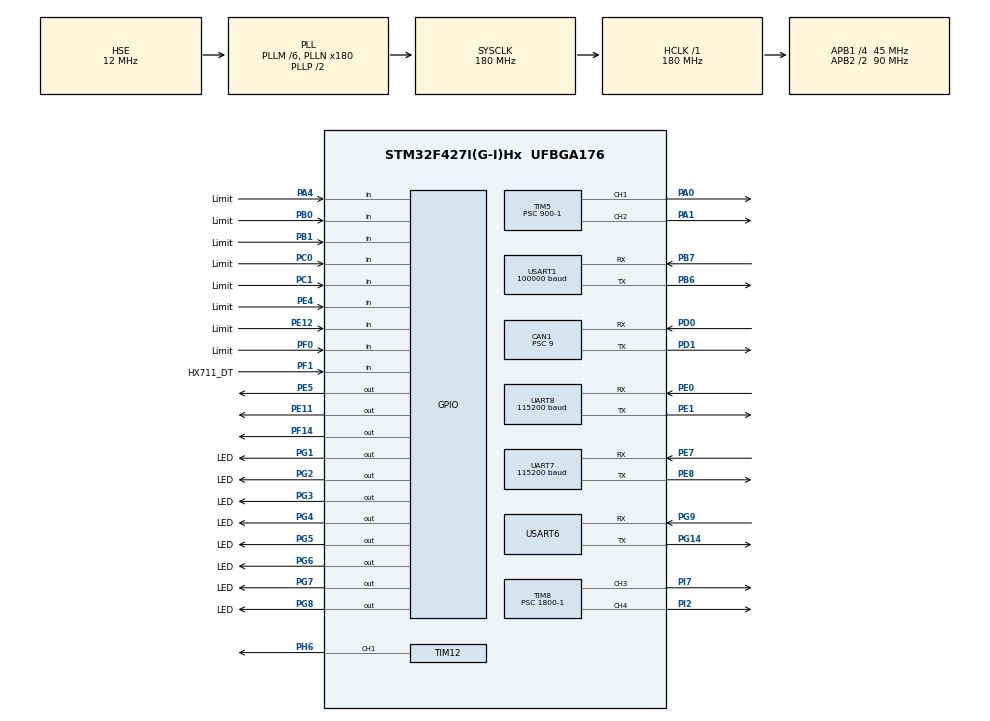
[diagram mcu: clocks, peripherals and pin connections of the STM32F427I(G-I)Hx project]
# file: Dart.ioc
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CAN1.BS1=CAN_BS1_2TQ
CAN1.BS2=CAN_BS2_2TQ
CAN1.CalculateBaudRate=1000000
CAN1.CalculateTimeBit=1000
CAN1.CalculateTimeQuantum=200.0
CAN1.Prescaler=9
Dma.Request0=UART8_RX
Dma.Request1=USART1_RX
Dma.Request2=UART8_TX
Dma.Request3=UART7_RX
Dma.Request4=UART7_TX
Dma.UART7_RX.3.Direction=DMA_PERIPH_TO_MEMORY
Dma.UART7_RX.3.FIFOMode=DMA_FIFOMODE_DISABLE
Dma.UART7_RX.3.Instance=DMA1_Stream3
Dma.UART7_RX.3.MemDataAlignment=DMA_MDATAALIGN_BYTE
Dma.UART7_RX.3.MemInc=DMA_MINC_ENABLE
Dma.UART7_RX.3.Mode=DMA_CIRCULAR
Dma.UART7_RX.3.PeriphDataAlignment=DMA_PDATAALIGN_BYTE
Dma.UART7_RX.3.PeriphInc=DMA_PINC_DISABLE
Dma.UART7_RX.3.Priority=DMA_PRIORITY_VERY_HIGH
Dma.UART7_TX.4.Direction=DMA_MEMORY_TO_PERIPH
Dma.UART7_TX.4.FIFOMode=DMA_FIFOMODE_DISABLE
Dma.UART7_TX.4.Instance=DMA1_Stream1
Dma.UART7_TX.4.MemDataAlignment=DMA_MDATAALIGN_BYTE
Dma.UART7_TX.4.MemInc=DMA_MINC_ENABLE
Dma.UART7_TX.4.Mode=DMA_NORMAL
Dma.UART7_TX.4.PeriphDataAlignment=DMA_PDATAALIGN_BYTE
Dma.UART7_TX.4.PeriphInc=DMA_PINC_DISABLE
Dma.UART7_TX.4.Priority=DMA_PRIORITY_VERY_HIGH
Dma.UART8_RX.0.Direction=DMA_PERIPH_TO_MEMORY
Dma.UART8_RX.0.FIFOMode=DMA_FIFOMODE_DISABLE
Dma.UART8_RX.0.Instance=DMA1_Stream6
Dma.UART8_RX.0.MemDataAlignment=DMA_MDATAALIGN_BYTE
Dma.UART8_RX.0.MemInc=DMA_MINC_ENABLE
Dma.UART8_RX.0.Mode=DMA_NORMAL
Dma.UART8_RX.0.PeriphDataAlignment=DMA_PDATAALIGN_BYTE
Dma.UART8_RX.0.PeriphInc=DMA_PINC_DISABLE
Dma.UART8_RX.0.Priority=DMA_PRIORITY_VERY_HIGH
Dma.UART8_TX.2.Direction=DMA_MEMORY_TO_PERIPH
Dma.UART8_TX.2.FIFOMode=DMA_FIFOMODE_DISABLE
Dma.UART8_TX.2.Instance=DMA1_Stream0
Dma.UART8_TX.2.MemDataAlignment=DMA_MDATAALIGN_BYTE
Dma.UART8_TX.2.MemInc=DMA_MINC_ENABLE
Dma.UART8_TX.2.Mode=DMA_NORMAL
Dma.UART8_TX.2.PeriphDataAlignment=DMA_PDATAALIGN_BYTE
Dma.UART8_TX.2.PeriphInc=DMA_PINC_DISABLE
Dma.UART8_TX.2.Priority=DMA_PRIORITY_VERY_HIGH
Dma.USART1_RX.1.Direction=DMA_PERIPH_TO_MEMORY
Dma.USART1_RX.1.FIFOMode=DMA_FIFOMODE_DISABLE
Dma.USART1_RX.1.Instance=DMA2_Stream2
Dma.USART1_RX.1.MemDataAlignment=DMA_MDATAALIGN_BYTE
Dma.USART1_RX.1.MemInc=DMA_MINC_ENABLE
Dma.USART1_RX.1.Mode=DMA_NORMAL
Dma.USART1_RX.1.PeriphDataAlignment=DMA_PDATAALIGN_BYTE
Dma.USART1_RX.1.PeriphInc=DMA_PINC_DISABLE
Dma.USART1_RX.1.Priority=DMA_PRIORITY_VERY_HIGH
FREERTOS.Queues01=Queue_DT7ToGimbal,1,18,1,Dynamic,NULL,NULL
FREERTOS.Tasks01=MotorControlTask,24,512,Motor_Task_Entry,As weak,NULL,Dynamic,NULL,NULL;InfoReportTask,8,256,Info_Task_Entry,As weak,NULL,Dynamic,NULL,NULL;DartLogicTask,32,512,Dart_Task_Entry,As weak,NULL,Dynamic,NULL,NULL;UartSendTask,8,256,Uart_Task_Entry,As weak,NULL,Dynamic,NULL,NULL;VisionCommTask,40,128,Vision_Task_Entry,As weak,NULL,Dynamic,NULL,NULL;SystemMonitorTask,32,128,SystemMonitor_Task_Entry,As weak,NULL,Dynamic,NULL,NULL
FREERTOS.configTOTAL_HEAP_SIZE=10240
Mcu.Family=STM32F4
Mcu.Name=STM32F427I(G-I)Hx
Mcu.Package=UFBGA176
NVIC.CAN1_RX0_IRQn=true\:5\:0\:false\:false\:true\:true\:true\:true\:true
NVIC.CAN1_RX1_IRQn=true\:5\:0\:false\:false\:true\:true\:true\:true\:true
NVIC.DMA1_Stream0_IRQn=true\:5\:0\:false\:false\:true\:true\:false\:true\:true
NVIC.DMA1_Stream1_IRQn=true\:5\:0\:false\:false\:true\:true\:false\:true\:true
NVIC.DMA1_Stream3_IRQn=true\:5\:0\:false\:false\:true\:true\:false\:true\:true
NVIC.DMA1_Stream6_IRQn=true\:5\:0\:false\:false\:true\:true\:false\:true\:true
NVIC.DMA2_Stream2_IRQn=true\:5\:0\:false\:false\:true\:true\:false\:true\:true
NVIC.PriorityGroup=NVIC_PRIORITYGROUP_4
NVIC.TIM2_IRQn=true\:5\:0\:false\:false\:true\:true\:true\:true\:true
NVIC.TIM3_IRQn=true\:5\:0\:false\:false\:true\:true\:true\:true\:true
NVIC.TIM5_IRQn=true\:5\:0\:false\:false\:true\:true\:true\:true\:true
NVIC.TIM6_DAC_IRQn=true\:0\:0\:true\:false\:true\:false\:false\:true\:true
NVIC.TimeBase=TIM6_DAC_IRQn
NVIC.TimeBaseIP=TIM6
NVIC.UART7_IRQn=true\:5\:0\:false\:false\:true\:true\:true\:true\:true
NVIC.UART8_IRQn=true\:5\:0\:false\:false\:true\:true\:true\:true\:true
NVIC.USART1_IRQn=true\:5\:0\:false\:false\:true\:true\:true\:true\:true
NVIC.USART6_IRQn=true\:5\:0\:false\:false\:true\:true\:true\:true\:true
PA0/WKUP.GPIO_ModeDefaultPP=GPIO_MODE_AF_PP
PA0/WKUP.GPIO_PuPd=GPIO_NOPULL
PA0/WKUP.GPIO_Speed=GPIO_SPEED_FREQ_HIGH
PA0/WKUP.Signal=S_TIM5_CH1
PA1.GPIO_ModeDefaultPP=GPIO_MODE_AF_PP
PA1.GPIO_PuPd=GPIO_NOPULL
PA1.GPIO_Speed=GPIO_SPEED_FREQ_HIGH
PA1.Signal=S_TIM5_CH2
PA13.Mode=Serial_Wire
PA13.Signal=SYS_JTMS-SWDIO
PA14.Mode=Serial_Wire
PA14.Signal=SYS_JTCK-SWCLK
PA4.GPIO_Label=Limit
PA4.GPIO_Mode=GPIO_MODE_INPUT
PA4.GPIO_PuPd=GPIO_PULLUP
PA4.Signal=GPIO_Input
PB0.GPIO_Label=Limit
PB0.GPIO_Mode=GPIO_MODE_INPUT
PB0.GPIO_PuPd=GPIO_PULLUP
PB0.Signal=GPIO_Input
PB1.GPIO_Label=Limit
PB1.GPIO_Mode=GPIO_MODE_INPUT
PB1.GPIO_PuPd=GPIO_PULLUP
PB1.Signal=GPIO_Input
PB12.Signal=CAN2_RX
PB6.Mode=Asynchronous
PB6.Signal=USART1_TX
PB7.Mode=Asynchronous
PB7.Signal=USART1_RX
PC0.GPIO_Label=Limit
PC0.GPIO_Mode=GPIO_MODE_INPUT
PC0.GPIO_PuPd=GPIO_PULLUP
PC0.Signal=GPIO_Input
PC1.GPIO_Label=Limit
PC1.GPIO_Mode=GPIO_MODE_INPUT
PC1.GPIO_PuPd=GPIO_PULLUP
PC1.Signal=GPIO_Input
PD0.Mode=CAN_Activate
PD0.Signal=CAN1_RX
PD1.Mode=CAN_Activate
PD1.Signal=CAN1_TX
PD8.Signal=USART3_TX
PD9.Signal=USART3_RX
PE0.Mode=Asynchronous
PE0.Signal=UART8_RX
PE1.Mode=Asynchronous
PE1.Signal=UART8_TX
PE11.PinState=GPIO_PIN_SET
PE11.Signal=GPIO_Output
PE12.GPIO_Label=Limit
PE12.GPIO_Mode=GPIO_MODE_INPUT
PE12.GPIO_PuPd=GPIO_PULLUP
PE12.Signal=GPIO_Input
PE4.GPIO_Label=Limit
PE4.GPIO_Mode=GPIO_MODE_INPUT
PE4.GPIO_PuPd=GPIO_PULLUP
PE4.Signal=GPIO_Input
PE5.GPIO_ModeDefaultOutputPP=GPIO_MODE_OUTPUT_PP
PE5.GPIO_Speed=GPIO_SPEED_FREQ_VERY_HIGH
PE5.PinState=GPIO_PIN_RESET
PE5.Signal=GPIO_Output
PE7.GPIO_PuPd=GPIO_PULLUP
PE7.Mode=Asynchronous
PE7.Signal=UART7_RX
PE8.Mode=Asynchronous
PE8.Signal=UART7_TX
PF0.GPIO_Label=Limit
PF0.GPIO_Mode=GPIO_MODE_INPUT
PF0.GPIO_PuPd=GPIO_PULLUP
PF0.Signal=GPIO_Input
PF1.GPIO_Label=HX711_DT
PF1.GPIO_PuPd=GPIO_PULLUP
PF1.Signal=GPIO_Input
PF14.PinState=GPIO_PIN_SET
PF14.Signal=GPIO_Output
PG1.GPIO_Label=LED
PG1.GPIO_ModeDefaultOutputPP=GPIO_MODE_OUTPUT_PP
PG1.GPIO_PuPd=GPIO_NOPULL
PG1.GPIO_Speed=GPIO_SPEED_FREQ_LOW
PG1.PinState=GPIO_PIN_SET
PG1.Signal=GPIO_Output
PG14.Mode=Asynchronous
PG14.Signal=USART6_TX
PG2.GPIO_Label=LED
PG2.GPIO_ModeDefaultOutputPP=GPIO_MODE_OUTPUT_PP
PG2.GPIO_PuPd=GPIO_NOPULL
PG2.GPIO_Speed=GPIO_SPEED_FREQ_LOW
PG2.PinState=GPIO_PIN_SET
PG2.Signal=GPIO_Output
PG3.GPIO_Label=LED
PG3.GPIO_ModeDefaultOutputPP=GPIO_MODE_OUTPUT_PP
PG3.GPIO_PuPd=GPIO_NOPULL
PG3.GPIO_Speed=GPIO_SPEED_FREQ_LOW
PG3.PinState=GPIO_PIN_SET
PG3.Signal=GPIO_Output
PG4.GPIO_Label=LED
PG4.GPIO_ModeDefaultOutputPP=GPIO_MODE_OUTPUT_PP
PG4.GPIO_PuPd=GPIO_NOPULL
PG4.GPIO_Speed=GPIO_SPEED_FREQ_LOW
PG4.PinState=GPIO_PIN_SET
PG4.Signal=GPIO_Output
PG5.GPIO_Label=LED
PG5.GPIO_ModeDefaultOutputPP=GPIO_MODE_OUTPUT_PP
PG5.GPIO_PuPd=GPIO_NOPULL
PG5.GPIO_Speed=GPIO_SPEED_FREQ_LOW
PG5.PinState=GPIO_PIN_SET
PG5.Signal=GPIO_Output
PG6.GPIO_Label=LED
PG6.GPIO_ModeDefaultOutputPP=GPIO_MODE_OUTPUT_PP
PG6.GPIO_PuPd=GPIO_NOPULL
PG6.GPIO_Speed=GPIO_SPEED_FREQ_LOW
PG6.PinState=GPIO_PIN_SET
PG6.Signal=GPIO_Output
PG7.GPIO_Label=LED
PG7.GPIO_ModeDefaultOutputPP=GPIO_MODE_OUTPUT_PP
PG7.GPIO_PuPd=GPIO_NOPULL
PG7.GPIO_Speed=GPIO_SPEED_FREQ_LOW
PG7.PinState=GPIO_PIN_SET
PG7.Signal=GPIO_Output
PG8.GPIO_Label=LED
PG8.GPIO_ModeDefaultOutputPP=GPIO_MODE_OUTPUT_PP
PG8.GPIO_PuPd=GPIO_NOPULL
PG8.GPIO_Speed=GPIO_SPEED_FREQ_LOW
PG8.PinState=GPIO_PIN_SET
PG8.Signal=GPIO_Output
PG9.Mode=Asynchronous
PG9.Signal=USART6_RX
PH0/OSC_IN.Mode=HSE-External-Oscillator
PH0/OSC_IN.Signal=RCC_OSC_IN
PH1/OSC_OUT.Mode=HSE-External-Oscillator
PH1/OSC_OUT.Signal=RCC_OSC_OUT
PH6.Signal=S_TIM12_CH1
PI2.Signal=S_TIM8_CH4
PI7.Signal=S_TIM8_CH3
ProjectManager.HeapSize=0x200
ProjectManager.StackSize=0x400
ProjectManager.TargetToolchain=MDK-ARM V5.32
RCC.48MHZClocksFreq_Value=90000000
RCC.AHBFreq_Value=180000000
RCC.APB1CLKDivider=RCC_HCLK_DIV4
RCC.APB1Freq_Value=45000000
RCC.APB1TimFreq_Value=90000000
RCC.APB2CLKDivider=RCC_HCLK_DIV2
RCC.APB2Freq_Value=90000000
RCC.APB2TimFreq_Value=180000000
RCC.CortexFreq_Value=180000000
RCC.HCLKFreq_Value=180000000
RCC.HSE_VALUE=12000000
RCC.HSI_VALUE=16000000
RCC.LSE_VALUE=32768
RCC.PLLM=6
RCC.PLLN=180
RCC.PLLSourceVirtual=RCC_PLLSOURCE_HSE
RCC.SYSCLKFreq_VALUE=180000000
RCC.SYSCLKSource=RCC_SYSCLKSOURCE_PLLCLK
RCC.VCOOutputFreq_Value=360000000
SH.S_TIM12_CH1.0=TIM12_CH1,PWM Generation1 CH1
SH.S_TIM5_CH1.0=TIM5_CH1,PWM Generation1 CH1
SH.S_TIM5_CH2.0=TIM5_CH2,PWM Generation2 CH2
SH.S_TIM8_CH3.0=TIM8_CH3,PWM Generation3 CH3
SH.S_TIM8_CH4.0=TIM8_CH4,PWM Generation4 CH4
STMicroelectronics.X-CUBE-ALGOBUILD.1.4.0.LibraryCcDSPOoLibraryJjDSPOoLibrary=true
TIM12.Channel-PWM\ Generation1\ CH1=TIM_CHANNEL_1
TIM12.Period=500-1
TIM12.Prescaler=180-1
TIM2.Period=1000-1
TIM2.Prescaler=90-1
TIM3.Period=1800
TIM3.Prescaler=1000
TIM5.Channel-PWM\ Generation1\ CH1=TIM_CHANNEL_1
TIM5.Channel-PWM\ Generation2\ CH2=TIM_CHANNEL_2
TIM5.Period=2000-1
TIM5.Prescaler=900-1
TIM8.Channel-PWM\ Generation3\ CH3=TIM_CHANNEL_3
TIM8.Channel-PWM\ Generation4\ CH4=TIM_CHANNEL_4
TIM8.Period=2000-1
TIM8.Prescaler=1800-1
UART7.BaudRate=115200
UART7.VirtualMode=Asynchronous
UART8.BaudRate=115200
UART8.VirtualMode=Asynchronous
USART1.BaudRate=100000
USART1.Parity=PARITY_EVEN
USART1.VirtualMode=VM_ASYNC
USART1.WordLength=WORDLENGTH_9B
USART6.VirtualMode=VM_ASYNC
VP_FREERTOS_VS_CMSIS_V2.Mode=CMSIS_V2
VP_STMicroelectronics.X-CUBE-ALGOBUILD_VS_DSPOoLibraryJjLibrary_1.4.0_1.4.0.Mode=DSPOoLibraryJjLibrary
VP_SYS_VS_tim6.Mode=TIM6
VP_TIM12_VS_ClockSourceINT.Mode=Internal
VP_TIM2_VS_ClockSourceINT.Mode=Internal
VP_TIM3_VS_ClockSourceINT.Mode=Internal
VP_TIM5_VS_ClockSourceINT.Mode=Internal
board=custom

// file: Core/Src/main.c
/* USER CODE BEGIN Header */
/**
 ******************************************************************************
 * @file           : main.c
 * @brief          : Main program body
 ******************************************************************************
 * @attention
 *
 * Copyright (c) 2025 STMicroelectronics.
 * All rights reserved.
 *
 * This software is licensed under terms that can be found in the LICENSE file
 * in the root directory of this software component.
 * If no LICENSE file comes with this software, it is provided AS-IS.
 *
 ******************************************************************************
 */
/* USER CODE END Header */
#include "main.h"
#include "cmsis_os.h"
#include "can.h"
#include "dma.h"
#include "tim.h"
#include "usart.h"
#include "gpio.h"

void SystemClock_Config(void);
void MX_FREERTOS_Init(void);

int main(void)
{

  /* MCU Configuration--------------------------------------------------------*/

  /* Reset of all peripherals, Initializes the Flash interface and the Systick. */
  HAL_Init();

  /* Configure the system clock */
  SystemClock_Config();

  /* Initialize all configured peripherals */
  MX_GPIO_Init();
  MX_DMA_Init();
  MX_CAN1_Init();
  MX_USART1_UART_Init();
  MX_UART7_Init();
  MX_UART8_Init();
  MX_TIM5_Init();
  MX_TIM2_Init();
  MX_TIM3_Init();
  MX_USART6_UART_Init();
  MX_TIM12_Init();
  MX_TIM8_Init();

  /* Init scheduler */
  osKernelInitialize();  /* Call init function for freertos objects (in cmsis_os2.c) */
  MX_FREERTOS_Init();

  /* Start scheduler */
  osKernelStart();

  /* We should never get here as control is now taken by the scheduler */

  /* Infinite loop */
  while (1)
  {

  }
}

void SystemClock_Config(void)
{
  RCC_OscInitTypeDef RCC_OscInitStruct = {0};
  RCC_ClkInitTypeDef RCC_ClkInitStruct = {0};

  /** Configure the main internal regulator output voltage
  */
  __HAL_RCC_PWR_CLK_ENABLE();
  __HAL_PWR_VOLTAGESCALING_CONFIG(PWR_REGULATOR_VOLTAGE_SCALE1);

  /** Initializes the RCC Oscillators according to the specified parameters
  * in the RCC_OscInitTypeDef structure.
  */
  RCC_OscInitStruct.OscillatorType = RCC_OSCILLATORTYPE_HSE;
  RCC_OscInitStruct.HSEState = RCC_HSE_ON;
  RCC_OscInitStruct.PLL.PLLState = RCC_PLL_ON;
  RCC_OscInitStruct.PLL.PLLSource = RCC_PLLSOURCE_HSE;
  RCC_OscInitStruct.PLL.PLLM = 6;
  RCC_OscInitStruct.PLL.PLLN = 180;
  RCC_OscInitStruct.PLL.PLLP = RCC_PLLP_DIV2;
  RCC_OscInitStruct.PLL.PLLQ = 4;
  if (HAL_RCC_OscConfig(&RCC_OscInitStruct) != HAL_OK)
  {
    Error_Handler();
  }

  /** Activate the Over-Drive mode
  */
  if (HAL_PWREx_EnableOverDrive() != HAL_OK)
  {
    Error_Handler();
  }

  /** Initializes the CPU, AHB and APB buses clocks
  */
  RCC_ClkInitStruct.ClockType = RCC_CLOCKTYPE_HCLK|RCC_CLOCKTYPE_SYSCLK
                              |RCC_CLOCKTYPE_PCLK1|RCC_CLOCKTYPE_PCLK2;
  RCC_ClkInitStruct.SYSCLKSource = RCC_SYSCLKSOURCE_PLLCLK;
  RCC_ClkInitStruct.AHBCLKDivider = RCC_SYSCLK_DIV1;
  RCC_ClkInitStruct.APB1CLKDivider = RCC_HCLK_DIV4;
  RCC_ClkInitStruct.APB2CLKDivider = RCC_HCLK_DIV2;

  if (HAL_RCC_ClockConfig(&RCC_ClkInitStruct, FLASH_LATENCY_5) != HAL_OK)
  {
    Error_Handler();
  }
}

void HAL_TIM_PeriodElapsedCallback(TIM_HandleTypeDef *htim)
{
  if (htim->Instance == TIM6)
  {
    HAL_IncTick();
  }
}

void Error_Handler(void)
{
  __disable_irq();
  while (1)
  {
  }
}

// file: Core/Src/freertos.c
/* USER CODE BEGIN Header */
/**
  ******************************************************************************
  * File Name          : freertos.c
  * Description        : Code for freertos applications
  ******************************************************************************
  * @attention
  *
  * Copyright (c) 2025 STMicroelectronics.
  * All rights reserved.
  *
  * This software is licensed under terms that can be found in the LICENSE file
  * in the root directory of this software component.
  * If no LICENSE file comes with this software, it is provided AS-IS.
  *
  ******************************************************************************
  */
/* USER CODE END Header */

#include "FreeRTOS.h"
#include "task.h"
#include "main.h"
#include "cmsis_os.h"

/* Definitions for MotorControlTask */
osThreadId_t MotorControlTaskHandle;
const osThreadAttr_t MotorControlTask_attributes = {
  .name = "MotorControlTask",
  .stack_size = 512 * 4,
  .priority = (osPriority_t) osPriorityNormal,
};
/* Definitions for InfoReportTask */
osThreadId_t InfoReportTaskHandle;
const osThreadAttr_t InfoReportTask_attributes = {
  .name = "InfoReportTask",
  .stack_size = 256 * 4,
  .priority = (osPriority_t) osPriorityLow,
};
/* Definitions for DartLogicTask */
osThreadId_t DartLogicTaskHandle;
const osThreadAttr_t DartLogicTask_attributes = {
  .name = "DartLogicTask",
  .stack_size = 512 * 4,
  .priority = (osPriority_t) osPriorityAboveNormal,
};
/* Definitions for UartSendTask */
osThreadId_t UartSendTaskHandle;
const osThreadAttr_t UartSendTask_attributes = {
  .name = "UartSendTask",
  .stack_size = 256 * 4,
  .priority = (osPriority_t) osPriorityLow,
};
/* Definitions for VisionCommTask */
osThreadId_t VisionCommTaskHandle;
const osThreadAttr_t VisionCommTask_attributes = {
  .name = "VisionCommTask",
  .stack_size = 128 * 4,
  .priority = (osPriority_t) osPriorityHigh,
};
/* Definitions for SystemMonitorTask */
osThreadId_t SystemMonitorTaskHandle;
const osThreadAttr_t SystemMonitorTask_attributes = {
  .name = "SystemMonitorTask",
  .stack_size = 128 * 4,
  .priority = (osPriority_t) osPriorityAboveNormal,
};
/* Definitions for Queue_DT7ToGimbal */
osMessageQueueId_t Queue_DT7ToGimbalHandle;
const osMessageQueueAttr_t Queue_DT7ToGimbal_attributes = {
  .name = "Queue_DT7ToGimbal"
};

void Motor_Task_Entry(void *argument);
void Info_Task_Entry(void *argument);
void Dart_Task_Entry(void *argument);
void Uart_Task_Entry(void *argument);
void Vision_Task_Entry(void *argument);
void SystemMonitor_Task_Entry(void *argument);

void MX_FREERTOS_Init(void); /* (MISRA C 2004 rule 8.1) */

void MX_FREERTOS_Init(void) {

  /* Create the queue(s) */
  /* creation of Queue_DT7ToGimbal */
  Queue_DT7ToGimbalHandle = osMessageQueueNew (1, 18, &Queue_DT7ToGimbal_attributes);

  /* Create the thread(s) */
  /* creation of MotorControlTask */
  MotorControlTaskHandle = osThreadNew(Motor_Task_Entry, NULL, &MotorControlTask_attributes);

  /* creation of InfoReportTask */
  InfoReportTaskHandle = osThreadNew(Info_Task_Entry, NULL, &InfoReportTask_attributes);

  /* creation of DartLogicTask */
  DartLogicTaskHandle = osThreadNew(Dart_Task_Entry, NULL, &DartLogicTask_attributes);

  /* creation of UartSendTask */
  UartSendTaskHandle = osThreadNew(Uart_Task_Entry, NULL, &UartSendTask_attributes);

  /* creation of VisionCommTask */
  VisionCommTaskHandle = osThreadNew(Vision_Task_Entry, NULL, &VisionCommTask_attributes);

  /* creation of SystemMonitorTask */
  SystemMonitorTaskHandle = osThreadNew(SystemMonitor_Task_Entry, NULL, &SystemMonitorTask_attributes);

}

/* USER CODE BEGIN Header_Motor_Task_Entry */
/**
  * @brief  电机PID控制任务入口 (MotorControlTask)
  * @param  argument: Not used
  * @retval None
  */
/* USER CODE END Header_Motor_Task_Entry */
__weak void Motor_Task_Entry(void *argument)
{
  for(;;)
  {
    osDelay(1);
  }
}

/* USER CODE BEGIN Header_Info_Task_Entry */
/**
* @brief 系统事件与调试信息报告任务 (InfoReportTask)
* @param argument: Not used
* @retval None
*/
/* USER CODE END Header_Info_Task_Entry */
__weak void Info_Task_Entry(void *argument)
{
  for(;;)
  {
    osDelay(1);
  }
}

/* USER CODE BEGIN Header_Dart_Task_Entry */
/**
* @brief 飞镖主逻辑与状态机任务 (DartLogicTask)
* @param argument: Not used
* @retval None
*/
/* USER CODE END Header_Dart_Task_Entry */
__weak void Dart_Task_Entry(void *argument)
{
  for(;;)
  {
    osDelay(1);
  }
}

/* USER CODE BEGIN Header_Uart_Task_Entry */
/**
* @brief 串口数据发送任务 (UartSendTask)
* @param argument: Not used
* @retval None
*/
/* USER CODE END Header_Uart_Task_Entry */
__weak void Uart_Task_Entry(void *argument)
{
  for(;;)
  {
    osDelay(1);
  }
}

/* USER CODE BEGIN Header_Vision_Task_Entry */
/**
* @brief 视觉上位机通信任务 (VisionCommTask)
* @param argument: Not used
* @retval None
*/
/* USER CODE END Header_Vision_Task_Entry */
__weak void Vision_Task_Entry(void *argument)
{
  for(;;)
  {
    osDelay(1);
  }
}

/* USER CODE BEGIN Header_SystemMonitor_Task_Entry */
/**
* @brief 传感器轮询与蜂鸣器处理任务 (SystemTimerTask)
* @param argument: Not used
* @retval None
*/
/* USER CODE END Header_SystemMonitor_Task_Entry */
__weak void SystemMonitor_Task_Entry(void *argument)
{
  for(;;)
  {
    osDelay(1);
  }
}
